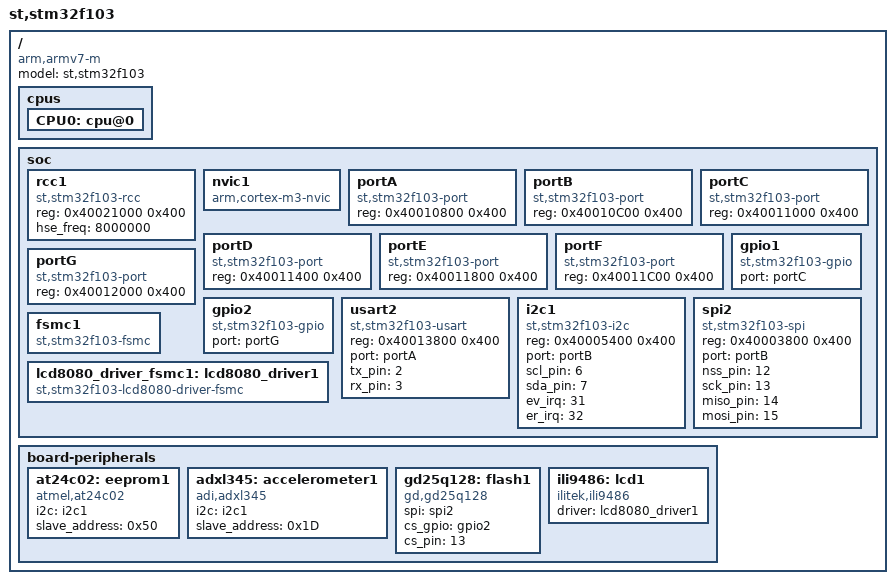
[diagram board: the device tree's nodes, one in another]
/dts-v1/;

/ {
    model = "st,stm32f103";
    compatible = "arm,armv7-m";

    cpus {
	    CPU0: cpu@0 {
	        device_type = "cpu";
	    };
	};
	
	soc {
		#address-cells = <1>;
		#size-cells = <1>;

	    rcc1: rcc1 {
	        device_type = "rcc";
	        compatible = "st,stm32f103-rcc";
			reg = <0x40021000 0x400>;
			hse_freq = <8000000>;
	    };

		nvic1: nvic1 {
			device_type = "pic";
			compatible = "arm,cortex-m3-nvic";
		};

		portA: portA {
			device_type = "port";
			compatible = "st,stm32f103-port";
			reg = <0x40010800 0x400>;
		};

		portB: portB {
			device_type = "port";
			compatible = "st,stm32f103-port";
			reg = <0x40010C00 0x400>;
		};

		portC: portC {
			device_type = "port";
			compatible = "st,stm32f103-port";
			reg = <0x40011000 0x400>;
		};

		portD: portD {
			device_type = "port";
			compatible = "st,stm32f103-port";
			reg = <0x40011400 0x400>;
		};

		portE: portE {
			device_type = "port";
			compatible = "st,stm32f103-port";
			reg = <0x40011800 0x400>;
		};

		portF: portF {
			device_type = "port";
			compatible = "st,stm32f103-port";
			reg = <0x40011C00 0x400>;
		};

		portG: portG {
			device_type = "port";
			compatible = "st,stm32f103-port";
			reg = <0x40012000 0x400>;
		};

		gpio1: gpio1 {
			device_type = "gpio";
			compatible = "st,stm32f103-gpio";
			port = "portC";
		};

		gpio2: gpio2 {
			device_type = "gpio";
			compatible = "st,stm32f103-gpio";
			port = "portG";
		};

	    usart2: usart2 {
	        device_type = "serial";
	        compatible = "st,stm32f103-usart";
			reg = <0x40013800 0x400>;
			port = "portA";
			tx_pin = <2>;
			rx_pin = <3>;
	    };

		i2c1: i2c1 {
			device_type = "i2c";
			compatible = "st,stm32f103-i2c";
			reg = <0x40005400 0x400>;
			port = "portB";
			scl_pin = <6>;
			sda_pin = <7>;
			ev_irq = <31>;
			er_irq = <32>;
		};

		spi2: spi2 {
			device_type = "spi";
			compatible = "st,stm32f103-spi";
			reg = <0x40003800 0x400>;
			port = "portB";
			nss_pin = <12>;
			sck_pin = <13>;
			miso_pin = <14>;
			mosi_pin = <15>;
		};

		fsmc1: fsmc1 {
			device_type = "fsmc";
			compatible = "st,stm32f103-fsmc";
		};

		lcd8080_driver_fsmc1: lcd8080_driver1 {
			device_type = "lcd8080-driver";
			compatible = "st,stm32f103-lcd8080-driver-fsmc";
		};
	};

	board-peripherals {
		#address-cells = <1>;
		#size-cells = <1>;

		at24c02: eeprom1 {
			device_type = "eeprom";
			compatible = "atmel,at24c02";
			i2c = "i2c1";
			slave_address = <0x50>;
		};

		adxl345: accelerometer1 {
			device_type = "accelerometer";
			compatible = "adi,adxl345";
			i2c = "i2c1";
			slave_address = <0x1D>;
		};

		gd25q128: flash1 {
			device_type = "flash";
			compatible = "gd,gd25q128";
			spi = "spi2";
			cs_gpio = "gpio2";
			cs_pin = <13>;
		};

		ili9486: lcd1 {
			device_type = "display";
			compatible = "ilitek,ili9486";
			driver = "lcd8080_driver1";
		};
	};
};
